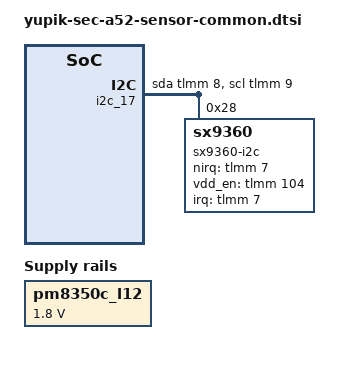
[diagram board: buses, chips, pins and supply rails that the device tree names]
/* Copyright (c) 2021, The Linux Foundation. All rights reserved.
 *
 * This program is free software; you can redistribute it and/or modify
 * it under the terms of the GNU General Public License version 2 and
 * only version 2 as published by the Free Software Foundation.
 *
 * This program is distributed in the hope that it will be useful,
 * but WITHOUT ANY WARRANTY; without even the implied warranty of
 * MERCHANTABILITY or FITNESS FOR A PARTICULAR PURPOSE.  See the
 * GNU General Public License for more details.
 */

&pm8350c_l12 {
	regulator-min-microvolt = <1800000>;
	regulator-max-microvolt = <1800000>;
	qcom,init-voltage = <1800000>;
	regulator-always-on;
};


&soc {
	i2c_17: i2c@17 { /* SW I2C */
		status = "ok";

		cell-index = <17>;
		compatible = "i2c-gpio";
		gpios = <&tlmm 8 0 /* sda */
			 &tlmm 9 0 /* scl */
		>;
		i2c-gpio,delay-us = <2>;
		address-cells = <1>;
		size-cells = <0>;
		pinctrl-names = "default";
		pinctrl-0 = <&grip_i2c_active>;

		sx9360-i2c@28 {
			compatible = "sx9360";
			reg = <0x28>;
			pinctrl-names = "default";
			pinctrl-0 = <&grip_int_active>;

			interrupt-parent = <&tlmm>;
			interrupts = <7 0>;

			sx9360,nirq-gpio = <&tlmm 7 0>;
			sx9360,reggnrlctrl2_reg = <0x32>;	/* scanperiod: 102ms */
			sx9360,againfreq_reg = <0x38>;		/* freq : 62.5 kHz, again : +/-7.5 pF */
			sx9360,refagainfreq_reg = <0x36>;	/* reference phase again : 5.25 pF, sampling freq : 83.33 khz */
			sx9360,gainrawfilt_reg = <0x1A>;	/* gain: x4, rawfilt : 1-1/4 */
			sx9360,refgainrawfilt_reg = <0x22>;	/* reference phase gain: x8, rawfilt : 1-1/4 */
			sx9360,proxthresh_reg = <0x1D>;		/* threshold: 420 */
			sx9360,hyst_reg = <0x35>;		/* hysteresis: +-25%, closedeb: 2 samples, fardeb: 2 samples */
			sx9360,regproxctrl3_reg = <0x0D>;	/* AVGPOSFILT: 1/512, AVGNEGFILT: 1/2 */
			sx9360,resolution_reg = <0x0F>;		/* resolution: 1204 */
			sx9360,refresolution_reg = <0x0F>;	/* reference phase  resolution: 1204 */
			sx9360,vdd_en = <&tlmm 104 0>;
		};
	};
};

